# CM_CORE__DSS register map
Vendor: Texas Instruments
Peripheral module from a debugger description file (folder am572x).
Registers are 32-bit, access per field, reset 0x70000 unless marked. A register's access mark holds for its fields unless they carry their own. Offsets are as the file gives them; lines under a group give offsets from that group; [hi:lo] are bit positions; {n}, {i} and the like mark numbered series; 'fields as' and 'values as' point back to an identical list; <NAME> marks a mode.

## CM_CORE__DSS
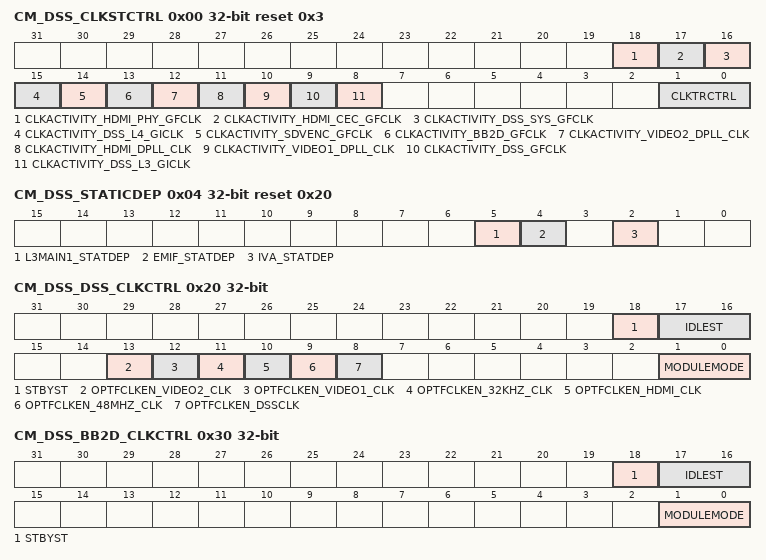
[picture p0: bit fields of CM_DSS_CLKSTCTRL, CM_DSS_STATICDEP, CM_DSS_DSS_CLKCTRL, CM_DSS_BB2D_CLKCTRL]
0x00 CM_DSS_CLKSTCTRL reset 0x3 — This register enables the DSS domain power state transition. It controls the HW supervised domain power state transition between ON-ACTIVE and ON-INACTIVE states. It also hold one status bit per clock input of the domain.
  [18] CLKACTIVITY_HDMI_PHY_GFCLK ro — This field indicates the state of the HDMI_PHY_GFCLK clock in the domain. [warm reset insensitive]
    0=INACT (Corresponding clock is definitely gated); 1=ACT (Corresponding clock is running or gating/ungating transition is on-going)
  [17] CLKACTIVITY_HDMI_CEC_GFCLK ro — This field indicates the state of the HDMI_CEC_GFCLK clock in the domain. [warm reset insensitive]
    values as CLKACTIVITY_HDMI_PHY_GFCLK
  [16] CLKACTIVITY_DSS_SYS_GFCLK ro — This field indicates the state of the DSS_SYS_GFCLK clock in the domain. [warm reset insensitive]
    0=Corresponding_clock_is_definitely_gated; 1=Corresponding clock is running or gating/ungating transition is on-going
  [15] CLKACTIVITY_DSS_L4_GICLK ro — This field indicates the state of the DSS_L4_GICLK clock in the domain. [warm reset insensitive]
    values as CLKACTIVITY_HDMI_PHY_GFCLK
  [14] CLKACTIVITY_SDVENC_GFCLK ro — This field indicates the state of the SDVENC_GFCLK clock in the domain. [warm reset insensitive]
    values as CLKACTIVITY_DSS_SYS_GFCLK
  [13] CLKACTIVITY_BB2D_GFCLK ro — This field indicates the state of the BB2D_GFCLK clock in the domain. [warm reset insensitive]
    values as CLKACTIVITY_HDMI_PHY_GFCLK
  [12] CLKACTIVITY_VIDEO2_DPLL_CLK ro — This field indicates the state of the VIDEO2_DPLL_CLK clock in the domain. [warm reset insensitive]
    values as CLKACTIVITY_HDMI_PHY_GFCLK
  [11] CLKACTIVITY_HDMI_DPLL_CLK ro — This field indicates the state of the HDMI_DPLL_CLK clock in the domain. [warm reset insensitive]
    values as CLKACTIVITY_HDMI_PHY_GFCLK
  [10] CLKACTIVITY_VIDEO1_DPLL_CLK ro — This field indicates the state of the VIDEO1_DPLL_CLK clock in the domain. [warm reset insensitive]
    values as CLKACTIVITY_HDMI_PHY_GFCLK
  [9] CLKACTIVITY_DSS_GFCLK ro — This field indicates the state of the DSS_GFCLK clock in the domain. [warm reset insensitive]
    values as CLKACTIVITY_HDMI_PHY_GFCLK
  [8] CLKACTIVITY_DSS_L3_GICLK ro — This field indicates the state of the DSS_L3_GICLK clock in the domain. [warm reset insensitive]
    values as CLKACTIVITY_HDMI_PHY_GFCLK
  [1:0] CLKTRCTRL rw — Controls the clock state transition of the DSS clock domain.
    0=NO_SLEEP (NO_SLEEP: Sleep transition cannot be initiated. Wakeup transition may however occur.); 1=SW_SLEEP (SW_SLEEP: Start a software forced sleep transition on the domain.); 2=SW_WKUP (SW_WKUP: Start a software forced wake-up transition on the domain.); 3=HW_AUTO (HW_AUTO: Automatic transition is enabled. Sleep and wakeup transition are based upon hardware conditions.)
0x04 CM_DSS_STATICDEP reset 0x20 — This register controls the static domain depedencies from DSS domain towards 'target' domains. It is relevant only for domain having system initiator(s).
  [5] L3MAIN1_STATDEP ro — Static dependency towards L3MAIN1 clock domain
    1=ENABLED (Dependency is enabled)
  [4] EMIF_STATDEP rw — Static dependency towards EMIF clock domain
    0=DISABLED (Dependency is disabled); 1=ENABLED (Dependency is enabled)
  [2] IVA_STATDEP rw — Static dependency towards IVA clock domain
    values as EMIF_STATDEP
0x08 CM_DSS_DYNAMICDEP ro reset 0x0 — This register controls the dynamic domain depedencies from DSS domain towards 'target' domains. It is relevant only for domain having OCP master port(s).
  [5] L3MAIN1_DYNDEP — Dynamic dependency towards L3MAIN1 domain
    0=DISABLED (Dependency is disabled)
0x20 CM_DSS_DSS_CLKCTRL — This register manages the DSS clocks.
  [18] STBYST ro — Module standby status. [warm reset insensitive]
    0=FUNC (Module is functional (not in standby)); 1=STANDBY (Module is in standby)
  [17:16] IDLEST ro — Module idle status. [warm reset insensitive]
    0=FUNC (Module is fully functional, including OCP); 1=TRANS (Module is performing transition: wakeup, or sleep, or sleep abortion); 2=IDLE (Module is in Idle mode (only OCP part). It is functional if using separate functional clock); 3=DISABLE (Module is disabled and cannot be accessed)
  [13] OPTFCLKEN_VIDEO2_CLK rw — Optional functional clock control.
    0=FCLK_DIS (Optional functional clock is disabled); 1=FCLK_EN (Optional functional clock is enabled)
  [12] OPTFCLKEN_VIDEO1_CLK rw — Optional functional clock control.
    values as OPTFCLKEN_VIDEO2_CLK
  [11] OPTFCLKEN_32KHZ_CLK rw — Optional functional clock control.
    values as OPTFCLKEN_VIDEO2_CLK
  [10] OPTFCLKEN_HDMI_CLK rw — Optional functional clock control.
    values as OPTFCLKEN_VIDEO2_CLK
  [9] OPTFCLKEN_48MHZ_CLK rw — Optional functional clock control.
    values as OPTFCLKEN_VIDEO2_CLK
  [8] OPTFCLKEN_DSSCLK rw — Optional functional clock control.
    values as OPTFCLKEN_VIDEO2_CLK
  [1:0] MODULEMODE rw — Control the way mandatory clocks are managed.
    0=DISABLED (Module is disabled by SW. Any OCP access to module results in an error, except if resulting from a module wakeup (asynchronous wakeup).); 2=ENABLED (Module is explicitly enabled. Interface clock (if not used for functions) may be gated according to the clock domain state. Functional clocks are guaranteed to stay present. As long as in this configuration, power domain sleep transition cannot happen.)
0x30 CM_DSS_BB2D_CLKCTRL — This register manages the BB2D clocks.
  [18] STBYST ro — Module standby status. [warm reset insensitive]
    values as CM_DSS_DSS_CLKCTRL.STBYST
  [17:16] IDLEST ro — Module idle status. [warm reset insensitive]
    values as CM_DSS_DSS_CLKCTRL.IDLEST
  [1:0] MODULEMODE rw — Control the way mandatory clocks are managed.
    values as CM_DSS_DSS_CLKCTRL.MODULEMODE
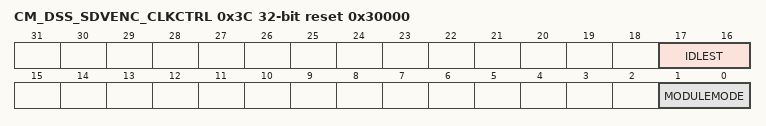
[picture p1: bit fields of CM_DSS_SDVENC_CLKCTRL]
0x3C CM_DSS_SDVENC_CLKCTRL reset 0x30000 — This register manages the SDVENC clocks.
  [17:16] IDLEST ro — Module idle status. [warm reset insensitive]
    values as CM_DSS_DSS_CLKCTRL.IDLEST
  [1:0] MODULEMODE rw — Control the way mandatory clocks are managed.
    0=DISABLED (Module is disabled by SW. Any OCP access to module results in an error, except if resulting from a module wakeup (asynchronous wakeup).); 2=ENABLE (Module is explicitly enabled. Interface clock (if not used for functions) may be gated according to the clock domain state. Functional clocks are guarantied to stay present. As long as in this configuration, power domain sleep transition cannot happen.)
